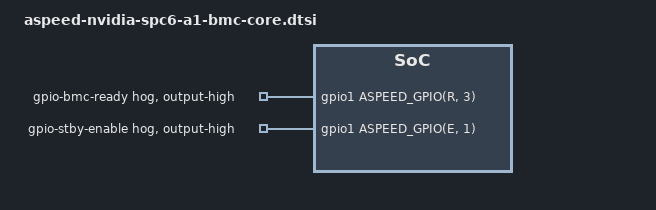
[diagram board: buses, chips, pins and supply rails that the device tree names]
// SPDX-License-Identifier: GPL-2.0+
/dts-v1/;

#include "aspeed-g7.dtsi"
#include <dt-bindings/gpio/aspeed-gpio.h>

&gpio1 {
	gpio-line-names =

	/* gpio-line-names are the combination of <signal>-<I/O> , "" is the placeholder for the unused pins*/

	/* 208 (26*8) 3.3V GPIOs */

	/*A0-A7*/
	"", "", "", "", "", "", "", "",

	/*B0-B7*/
	"", "", "", "", "", "", "", "",

	/*C0-C7*/
	"", "", "", "", "", "", "", "",

	/*D0-D7*/
	"", "", "", "", "", "", "", "",

	/*E0-E7*/
	"", "GP_BMC_STBY_PWR_EN", "GP_STBY_PG", "GP_BMC_PRESNT0_L", "", "", "", "",

	/*F0-F7*/
	"", "", "", "", "", "", "", "",

	/*G0-G7*/
	"", "", "", "", "", "", "", "",

	/*H0-H7*/
	"", "", "", "", "", "", "", "",

	/*I0-I7*/
	"", "", "", "", "", "", "", "",

	/*J0-J7*/
	"", "", "", "", "", "", "", "",

	/*K0-K7*/
	"", "", "", "", "", "", "", "",

	/*L0-L7*/
	"", "", "", "", "", "", "", "",

	/*M0-M7*/
	"", "", "", "", "", "", "", "",

	/*N0-N7*/
	"", "", "", "", "", "", "", "",

	/*O0-O7*/
	"", "", "", "", "", "", "", "",

	/*P0-P7*/
	"", "", "", "", "", "", "", "",

	/*Q0-Q7*/
	"", "", "", "", "", "", "", "",

	/*R0-R7*/
	"GP_BMC_EXP_INT_L", "", "", "GP_BMC_READY", "GP_APML_SMB_ALERT_L", "", "", "GP_MGMT_CPLD_BMC_INT_L",

	/*S0-S7*/
	"GP_BMC_GPIO_EXP_RESET_L", "GP_BMC_PWR_CYCLE_BMC", "", "", "", "", "", "",

	/*T0-T7*/
	"", "", "", "", "", "", "", "",

	/*U0-U7*/
	"", "", "", "", "", "", "", "",

	/*V0-V7*/
	"", "", "", "", "", "", "", "",

	/*W0-W7*/
	"", "", "", "", "", "", "", "",

	/*X0-X7*/
	"", "", "", "", "", "", "", "",

	/*Y0-Y7*/
	"", "", "", "", "", "", "", "",

	/*Z0-Z7*/
	"", "", "", "", "", "", "", "";

	bmc_ready {
		gpio-hog;
		gpios = <ASPEED_GPIO(R, 3) GPIO_TRANSITORY>;
		output-high;
		line-name = "gpio-bmc-ready";
	};

	stby_enable {
		gpio-hog;
		gpios = <ASPEED_GPIO(E, 1) GPIO_TRANSITORY>;
		output-high;
		line-name = "gpio-stby-enable";
	};

};

&gpio0 {
	/* 36 1.8V GPIOs */
	gpio-line-names =
	/*A0-A7*/
	"", "", "", "", "", "", "", "",

	/*B0-B7*/
	"", "", "", "", "", "", "", "",

	/*C0-C7*/
	"", "", "", "", "", "", "", "",

	/*D0-D7*/
	"", "", "", "", "", "", "", "",

	/*E0-E7*/
	"", "", "", "", "", "", "", "";
};
